AUTOSAR XML (schema 4-3-0)
package /ComponentTypes
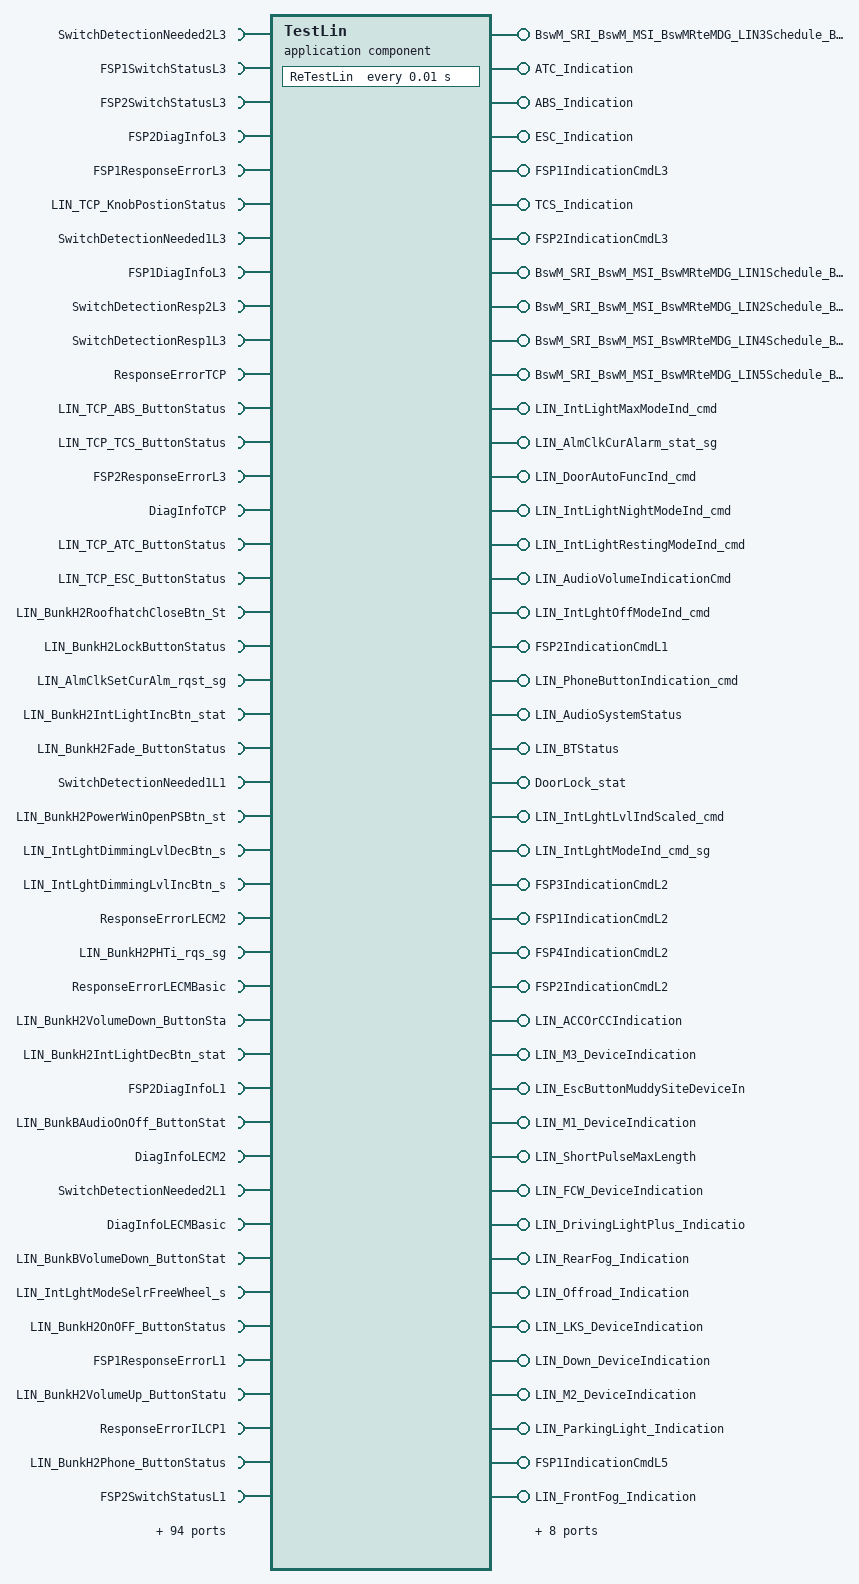
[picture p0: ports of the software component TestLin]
  application sw component type TestLin
    provide port BswM_SRI_BswM_MSI_BswMRteMDG_LIN3Schedule_BswM_MDGP_BswMRteMDG_LIN3Schedule: nonqueued-sender-com-spec=requestedMode, provided-interface=BswM_SRI_BswM_MSI_BswMRteMDG_LIN3Schedule_BswM_MDGP_BswMRteMDG_LIN3Schedule
    17 x require port:
      SwitchDetectionNeeded2L3: nonqueued-receiver-com-spec{data-element=SwitchDetectionNeeded2L3, init-value=0}, required-interface=SwitchDetectionNeeded2L3
      FSP1SwitchStatusL3: nonqueued-receiver-com-spec{data-element=FSP1SwitchStatusL3, init-value=0}, required-interface=FSP1SwitchStatusL3
      FSP2SwitchStatusL3: nonqueued-receiver-com-spec{data-element=FSP2SwitchStatusL3, init-value=0}, required-interface=FSP2SwitchStatusL3
      FSP2DiagInfoL3: nonqueued-receiver-com-spec{data-element=FSP2DiagInfoL3, init-value=0}, required-interface=FSP2DiagInfoL3
      FSP1ResponseErrorL3: nonqueued-receiver-com-spec{data-element=FSP1ResponseErrorL3, init-value=0}, required-interface=FSP1ResponseErrorL3
      LIN_TCP_KnobPostionStatus: nonqueued-receiver-com-spec{data-element=LIN_TCP_KnobPostionStatus, init-value=7}, required-interface=LIN_TCP_KnobPostionStatus
      SwitchDetectionNeeded1L3: nonqueued-receiver-com-spec{data-element=SwitchDetectionNeeded1L3, init-value=0}, required-interface=SwitchDetectionNeeded1L3
      FSP1DiagInfoL3: nonqueued-receiver-com-spec{data-element=FSP1DiagInfoL3, init-value=0}, required-interface=FSP1DiagInfoL3
      SwitchDetectionResp2L3: nonqueued-receiver-com-spec{data-element=SwitchDetectionResp2L3, init-value=8 x 0}, required-interface=SwitchDetectionResp2L3
      SwitchDetectionResp1L3: nonqueued-receiver-com-spec{data-element=SwitchDetectionResp1L3, init-value=8 x 0}, required-interface=SwitchDetectionResp1L3
      ResponseErrorTCP: nonqueued-receiver-com-spec{data-element=ResponseErrorTCP, init-value=0}, required-interface=ResponseErrorTCP
      LIN_TCP_ABS_ButtonStatus: nonqueued-receiver-com-spec{data-element=LIN_TCP_ABS_ButtonStatus, init-value=3}, required-interface=LIN_TCP_ABS_ButtonStatus
      LIN_TCP_TCS_ButtonStatus: nonqueued-receiver-com-spec{data-element=LIN_TCP_TCS_ButtonStatus, init-value=3}, required-interface=LIN_TCP_TCS_ButtonStatus
      FSP2ResponseErrorL3: nonqueued-receiver-com-spec{data-element=FSP2ResponseErrorL3, init-value=0}, required-interface=FSP2ResponseErrorL3
      DiagInfoTCP: nonqueued-receiver-com-spec{data-element=DiagInfoTCP, init-value=0}, required-interface=DiagInfoTCP
      LIN_TCP_ATC_ButtonStatus: nonqueued-receiver-com-spec{data-element=LIN_TCP_ATC_ButtonStatus, init-value=3}, required-interface=LIN_TCP_ATC_ButtonStatus
      LIN_TCP_ESC_ButtonStatus: nonqueued-receiver-com-spec{data-element=LIN_TCP_ESC_ButtonStatus, init-value=3}, required-interface=LIN_TCP_ESC_ButtonStatus
    10 x provide port:
      ATC_Indication: nonqueued-sender-com-spec{data-element=ATC_Indication, init-value=3}, provided-interface=ATC_Indication
      ABS_Indication: nonqueued-sender-com-spec{data-element=ABS_Indication, init-value=3}, provided-interface=ABS_Indication
      ESC_Indication: nonqueued-sender-com-spec{data-element=ESC_Indication, init-value=3}, provided-interface=ESC_Indication
      FSP1IndicationCmdL3: nonqueued-sender-com-spec{data-element=FSP1IndicationCmdL3, init-value=0}, provided-interface=FSP1IndicationCmdL3
      TCS_Indication: nonqueued-sender-com-spec{data-element=TCS_Indication, init-value=3}, provided-interface=TCS_Indication
      FSP2IndicationCmdL3: nonqueued-sender-com-spec{data-element=FSP2IndicationCmdL3, init-value=0}, provided-interface=FSP2IndicationCmdL3
      BswM_SRI_BswM_MSI_BswMRteMDG_LIN1Schedule_BswM_MDGP_BswMRteMDG_LIN1Schedule: nonqueued-sender-com-spec=requestedMode, provided-interface=BswM_SRI_BswM_MSI_BswMRteMDG_LIN1Schedule_BswM_MDGP_BswMRteMDG_LIN1Schedule
      BswM_SRI_BswM_MSI_BswMRteMDG_LIN2Schedule_BswM_MDGP_BswMRteMDG_LIN2Schedule: nonqueued-sender-com-spec=requestedMode, provided-interface=BswM_SRI_BswM_MSI_BswMRteMDG_LIN2Schedule_BswM_MDGP_BswMRteMDG_LIN2Schedule
      BswM_SRI_BswM_MSI_BswMRteMDG_LIN4Schedule_BswM_MDGP_BswMRteMDG_LIN4Schedule: nonqueued-sender-com-spec=requestedMode, provided-interface=BswM_SRI_BswM_MSI_BswMRteMDG_LIN4Schedule_BswM_MDGP_BswMRteMDG_LIN4Schedule
      BswM_SRI_BswM_MSI_BswMRteMDG_LIN5Schedule_BswM_MDGP_BswMRteMDG_LIN5Schedule: nonqueued-sender-com-spec=requestedMode, provided-interface=BswM_SRI_BswM_MSI_BswMRteMDG_LIN5Schedule_BswM_MDGP_BswMRteMDG_LIN5Schedule
    47 x require port:
      LIN_BunkH2RoofhatchCloseBtn_St: nonqueued-receiver-com-spec{data-element=LIN_BunkH2RoofhatchCloseBtn_St, init-value=3}, required-interface=LIN_BunkH2RoofhatchCloseBtn_St
      LIN_BunkH2LockButtonStatus: nonqueued-receiver-com-spec{data-element=LIN_BunkH2LockButtonStatus, init-value=3}, required-interface=LIN_BunkH2LockButtonStatus
      LIN_AlmClkSetCurAlm_rqst_sg: nonqueued-receiver-com-spec{data-element=LIN_AlmClkSetCurAlm_rqst_sg, init-value=fields=[LIN_AlmClkSetCurAlm_rqst_SetMin:63, LIN_AlmClkSetCurAlm_rqst_Type:7, LIN_AlmClkSetCurAlm_rqst_ID:127, LIN_AlmClkSetCurAlm_rqst_SetHr:31, LIN_AlmClkSetCurAlm_rqst_Stat:0]}, required-interface=LIN_AlmClkSetCurAlm_rqst_sg
      LIN_BunkH2IntLightIncBtn_stat: nonqueued-receiver-com-spec{data-element=LIN_BunkH2IntLightIncBtn_stat, init-value=3}, required-interface=LIN_BunkH2IntLightIncBtn_stat
      LIN_BunkH2Fade_ButtonStatus: nonqueued-receiver-com-spec{data-element=LIN_BunkH2Fade_ButtonStatus, init-value=3}, required-interface=LIN_BunkH2Fade_ButtonStatus
      SwitchDetectionNeeded1L1: nonqueued-receiver-com-spec{data-element=SwitchDetectionNeeded1L1, alive-timeout=120, init-value=0}, required-interface=SwitchDetectionNeeded1L1
      LIN_BunkH2PowerWinOpenPSBtn_st: nonqueued-receiver-com-spec{data-element=LIN_BunkH2PowerWinOpenPSBtn_st, init-value=3}, required-interface=LIN_BunkH2PowerWinOpenPSBtn_st
      LIN_IntLghtDimmingLvlDecBtn_s: nonqueued-receiver-com-spec{data-element=LIN_IntLghtDimmingLvlDecBtn_s, alive-timeout=120, init-value=3}, required-interface=LIN_IntLghtDimmingLvlDecBtn_s
      LIN_IntLghtDimmingLvlIncBtn_s: nonqueued-receiver-com-spec{data-element=LIN_IntLghtDimmingLvlIncBtn_s, alive-timeout=120, init-value=3}, required-interface=LIN_IntLghtDimmingLvlIncBtn_s
      ResponseErrorLECM2: nonqueued-receiver-com-spec{data-element=ResponseErrorLECM2, init-value=0}, required-interface=ResponseErrorLECM2
      LIN_BunkH2PHTi_rqs_sg: nonqueued-receiver-com-spec{data-element=LIN_BunkH2PHTi_rqs_sg, init-value=fields=[LIN_BunkH2PHTi_rqs_StartTimeHr:255, LIN_BunkH2PHTi_rqs_Timer_cmd:7, LIN_BunkH2PHTi_rqs_DurnTimeHr:255, LIN_BunkH2PHTi_rqs_StartTimeMin:255, LIN_BunkH2PHTi_rqs_DurnTimeMin:255]}, required-interface=LIN_BunkH2PHTi_rqs_sg
      ResponseErrorLECMBasic: nonqueued-receiver-com-spec{data-element=ResponseErrorLECMBasic, init-value=0}, required-interface=ResponseErrorLECMBasic
      LIN_BunkH2VolumeDown_ButtonSta: nonqueued-receiver-com-spec{data-element=LIN_BunkH2VolumeDown_ButtonSta, init-value=3}, required-interface=LIN_BunkH2VolumeDown_ButtonSta
      LIN_BunkH2IntLightDecBtn_stat: nonqueued-receiver-com-spec{data-element=LIN_BunkH2IntLightDecBtn_stat, init-value=3}, required-interface=LIN_BunkH2IntLightDecBtn_stat
      FSP2DiagInfoL1: nonqueued-receiver-com-spec{data-element=FSP2DiagInfoL1, alive-timeout=120, init-value=0}, required-interface=FSP2DiagInfoL1
      LIN_BunkBAudioOnOff_ButtonStat: nonqueued-receiver-com-spec{data-element=LIN_BunkBAudioOnOff_ButtonStat, init-value=3}, required-interface=LIN_BunkBAudioOnOff_ButtonStat
      DiagInfoLECM2: nonqueued-receiver-com-spec{data-element=DiagInfoLECM2, init-value=0}, required-interface=DiagInfoLECM2
      SwitchDetectionNeeded2L1: nonqueued-receiver-com-spec{data-element=SwitchDetectionNeeded2L1, alive-timeout=120, init-value=0}, required-interface=SwitchDetectionNeeded2L1
      DiagInfoLECMBasic: nonqueued-receiver-com-spec{data-element=DiagInfoLECMBasic, init-value=0}, required-interface=DiagInfoLECMBasic
      LIN_BunkBVolumeDown_ButtonStat: nonqueued-receiver-com-spec{data-element=LIN_BunkBVolumeDown_ButtonStat, init-value=3}, required-interface=LIN_BunkBVolumeDown_ButtonStat
      LIN_IntLghtModeSelrFreeWheel_s: nonqueued-receiver-com-spec{data-element=LIN_IntLghtModeSelrFreeWheel_s, alive-timeout=140, init-value=15}, required-interface=LIN_IntLghtModeSelrFreeWheel_s
      LIN_BunkH2OnOFF_ButtonStatus: nonqueued-receiver-com-spec{data-element=LIN_BunkH2OnOFF_ButtonStatus, init-value=3}, required-interface=LIN_BunkH2OnOFF_ButtonStatus
      FSP1ResponseErrorL1: nonqueued-receiver-com-spec{data-element=FSP1ResponseErrorL1, alive-timeout=140, init-value=0}, required-interface=FSP1ResponseErrorL1
      LIN_BunkH2VolumeUp_ButtonStatu: nonqueued-receiver-com-spec{data-element=LIN_BunkH2VolumeUp_ButtonStatu, init-value=3}, required-interface=LIN_BunkH2VolumeUp_ButtonStatu
      ResponseErrorILCP1: nonqueued-receiver-com-spec{data-element=ResponseErrorILCP1, alive-timeout=120, init-value=0}, required-interface=ResponseErrorILCP1
      LIN_BunkH2Phone_ButtonStatus: nonqueued-receiver-com-spec{data-element=LIN_BunkH2Phone_ButtonStatus, init-value=3}, required-interface=LIN_BunkH2Phone_ButtonStatus
      FSP2SwitchStatusL1: nonqueued-receiver-com-spec{data-element=FSP2SwitchStatusL1, alive-timeout=140, init-value=0}, required-interface=FSP2SwitchStatusL1
      FSP2ResponseErrorL1: nonqueued-receiver-com-spec{data-element=FSP2ResponseErrorL1, alive-timeout=140, init-value=0}, required-interface=FSP2ResponseErrorL1
      LIN_BunkH2PowerWinCloseDSBtn_s: nonqueued-receiver-com-spec{data-element=LIN_BunkH2PowerWinCloseDSBtn_s, init-value=3}, required-interface=LIN_BunkH2PowerWinCloseDSBtn_s
      LIN_BunkH2PowerWinOpenDSBtn_st: nonqueued-receiver-com-spec{data-element=LIN_BunkH2PowerWinOpenDSBtn_st, init-value=3}, required-interface=LIN_BunkH2PowerWinOpenDSBtn_st
      LIN_DoorAutoFuncBtn_stat: nonqueued-receiver-com-spec{data-element=LIN_DoorAutoFuncBtn_stat, alive-timeout=120, init-value=3}, required-interface=LIN_DoorAutoFuncBtn_stat
      LIN_BunkH2TempDec_ButtonStatus: nonqueued-receiver-com-spec{data-element=LIN_BunkH2TempDec_ButtonStatus, init-value=3}, required-interface=LIN_BunkH2TempDec_ButtonStatus
      LIN_BunkBVolumeUp_ButtonStat: nonqueued-receiver-com-spec{data-element=LIN_BunkBVolumeUp_ButtonStat, init-value=3}, required-interface=LIN_BunkBVolumeUp_ButtonStat
      LIN_BunkBIntLightActvnBtn_stat: nonqueued-receiver-com-spec{data-element=LIN_BunkBIntLightActvnBtn_stat, init-value=3}, required-interface=LIN_BunkBIntLightActvnBtn_stat
      LIN_BunkH2PowerWinClosePSBtn_s: nonqueued-receiver-com-spec{data-element=LIN_BunkH2PowerWinClosePSBtn_s, init-value=3}, required-interface=LIN_BunkH2PowerWinClosePSBtn_s
      LIN_BunkBParkHeater_ButtonStat: nonqueued-receiver-com-spec{data-element=LIN_BunkBParkHeater_ButtonStat, init-value=3}, required-interface=LIN_BunkBParkHeater_ButtonStat
      LIN_BunkH2ParkHeater_ButtonSta: nonqueued-receiver-com-spec{data-element=LIN_BunkH2ParkHeater_ButtonSta, init-value=3}, required-interface=LIN_BunkH2ParkHeater_ButtonSta
      LIN_BunkBTempInc_ButtonStat: nonqueued-receiver-com-spec{data-element=LIN_BunkBTempInc_ButtonStat, init-value=3}, required-interface=LIN_BunkBTempInc_ButtonStat
      LIN_BunkH2AudioOnOff_ButtonSta: nonqueued-receiver-com-spec{data-element=LIN_BunkH2AudioOnOff_ButtonSta, init-value=3}, required-interface=LIN_BunkH2AudioOnOff_ButtonSta
      SwitchDetectionResp2L1: nonqueued-receiver-com-spec{data-element=SwitchDetectionResp2L1, init-value=8 x 0}, required-interface=SwitchDetectionResp2L1
      LIN_BunkH2IntLightActvnBtn_sta: nonqueued-receiver-com-spec{data-element=LIN_BunkH2IntLightActvnBtn_sta, init-value=3}, required-interface=LIN_BunkH2IntLightActvnBtn_sta
      LIN_BunkH2RoofhatchOpenBtn_Sta: nonqueued-receiver-com-spec{data-element=LIN_BunkH2RoofhatchOpenBtn_Sta, init-value=3}, required-interface=LIN_BunkH2RoofhatchOpenBtn_Sta
      SwitchDetectionResp1L1: nonqueued-receiver-com-spec{data-element=SwitchDetectionResp1L1, init-value=8 x 0}, required-interface=SwitchDetectionResp1L1
      FSP1DiagInfoL1: nonqueued-receiver-com-spec{data-element=FSP1DiagInfoL1, alive-timeout=120, init-value=0}, required-interface=FSP1DiagInfoL1
      DiagInfoILCP1: nonqueued-receiver-com-spec{data-element=DiagInfoILCP1, alive-timeout=120, init-value=0}, required-interface=DiagInfoILCP1
      LIN_BunkBTempDec_ButtonStat: nonqueued-receiver-com-spec{data-element=LIN_BunkBTempDec_ButtonStat, init-value=3}, required-interface=LIN_BunkBTempDec_ButtonStat
      LIN_BunkH2TempInc_ButtonStatus: nonqueued-receiver-com-spec{data-element=LIN_BunkH2TempInc_ButtonStatus, init-value=3}, required-interface=LIN_BunkH2TempInc_ButtonStatus
    14 x provide port:
      LIN_IntLightMaxModeInd_cmd: nonqueued-sender-com-spec{data-element=LIN_IntLightMaxModeInd_cmd, init-value=0}, provided-interface=LIN_IntLightMaxModeInd_cmd
      LIN_AlmClkCurAlarm_stat_sg: nonqueued-sender-com-spec{data-element=LIN_AlmClkCurAlarm_stat_sg, init-value=fields=[LIN_AlmClkCurAlarm_stat_Stat:0, LIN_AlmClkCurAlarm_stat_SetHr:31, LIN_AlmClkCurAlarm_stat_Type:7, LIN_AlmClkCurAlarm_stat_SetMin:63, LIN_AlmClkCurAlarm_stat_ID:127]}, provided-interface=LIN_AlmClkCurAlarm_stat_sg
      LIN_DoorAutoFuncInd_cmd: nonqueued-sender-com-spec{data-element=LIN_DoorAutoFuncInd_cmd, init-value=0}, provided-interface=LIN_DoorAutoFuncInd_cmd
      LIN_IntLightNightModeInd_cmd: nonqueued-sender-com-spec{data-element=LIN_IntLightNightModeInd_cmd, init-value=0}, provided-interface=LIN_IntLightNightModeInd_cmd
      LIN_IntLightRestingModeInd_cmd: nonqueued-sender-com-spec{data-element=LIN_IntLightRestingModeInd_cmd, init-value=0}, provided-interface=LIN_IntLightRestingModeInd_cmd
      LIN_AudioVolumeIndicationCmd: nonqueued-sender-com-spec{data-element=LIN_AudioVolumeIndicationCmd, init-value=0}, provided-interface=LIN_AudioVolumeIndicationCmd
      LIN_IntLghtOffModeInd_cmd: nonqueued-sender-com-spec{data-element=LIN_IntLghtOffModeInd_cmd, init-value=0}, provided-interface=LIN_IntLghtOffModeInd_cmd
      FSP2IndicationCmdL1: nonqueued-sender-com-spec{data-element=FSP2IndicationCmdL1, init-value=0}, provided-interface=FSP2IndicationCmdL1
      LIN_PhoneButtonIndication_cmd: nonqueued-sender-com-spec{data-element=LIN_PhoneButtonIndication_cmd, init-value=0}, provided-interface=LIN_PhoneButtonIndication_cmd
      LIN_AudioSystemStatus: nonqueued-sender-com-spec{data-element=LIN_AudioSystemStatus, init-value=3}, provided-interface=LIN_AudioSystemStatus
      LIN_BTStatus: nonqueued-sender-com-spec{data-element=LIN_BTStatus, init-value=3}, provided-interface=LIN_BTStatus
      DoorLock_stat: nonqueued-sender-com-spec{data-element=DoorLock_stat, init-value=15}, provided-interface=DoorLock_stat
      LIN_IntLghtLvlIndScaled_cmd: nonqueued-sender-com-spec{data-element=LIN_IntLghtLvlIndScaled_cmd, init-value=0}, provided-interface=LIN_IntLghtLvlIndScaled_cmd
      LIN_IntLghtModeInd_cmd_sg: nonqueued-sender-com-spec{data-element=LIN_IntLghtModeInd_cmd_sg, init-value=fields=[LIN_IntLghtModeInd_cmd_EventFlag:0, LIN_IntLghtModeInd_cmd_IL_Mode:7]}, provided-interface=LIN_IntLghtModeInd_cmd_sg
    20 x require port:
      FSP3ResponseErrorL2: nonqueued-receiver-com-spec{data-element=FSP3ResponseErrorL2, init-value=0}, required-interface=FSP3ResponseErrorL2
      FSP1SwitchStatusL2: nonqueued-receiver-com-spec{data-element=FSP1SwitchStatusL2, init-value=0}, required-interface=FSP1SwitchStatusL2
      SwitchDetectionResp1L2: nonqueued-receiver-com-spec{data-element=SwitchDetectionResp1L2, init-value=8 x 0}, required-interface=SwitchDetectionResp1L2
      SwitchDetectionNeeded2L2: nonqueued-receiver-com-spec{data-element=SwitchDetectionNeeded2L2, init-value=0}, required-interface=SwitchDetectionNeeded2L2
      FSP3SwitchStatusL2: nonqueued-receiver-com-spec{data-element=FSP3SwitchStatusL2, init-value=0}, required-interface=FSP3SwitchStatusL2
      FSP3DiagInfoL2: nonqueued-receiver-com-spec{data-element=FSP3DiagInfoL2, init-value=0}, required-interface=FSP3DiagInfoL2
      FSP1DiagInfoL2: nonqueued-receiver-com-spec{data-element=FSP1DiagInfoL2, init-value=0}, required-interface=FSP1DiagInfoL2
      FSP4ResponseErrorL2: nonqueued-receiver-com-spec{data-element=FSP4ResponseErrorL2, init-value=0}, required-interface=FSP4ResponseErrorL2
      FSP4DiagInfoL2: nonqueued-receiver-com-spec{data-element=FSP4DiagInfoL2, init-value=0}, required-interface=FSP4DiagInfoL2
      FSP2DiagInfoL2: nonqueued-receiver-com-spec{data-element=FSP2DiagInfoL2, init-value=0}, required-interface=FSP2DiagInfoL2
      SwitchDetectionResp4L2: nonqueued-receiver-com-spec{data-element=SwitchDetectionResp4L2, init-value=8 x 0}, required-interface=SwitchDetectionResp4L2
      FSP4SwitchStatusL2: nonqueued-receiver-com-spec{data-element=FSP4SwitchStatusL2, init-value=0}, required-interface=FSP4SwitchStatusL2
      FSP1ResponseErrorL2: nonqueued-receiver-com-spec{data-element=FSP1ResponseErrorL2, init-value=0}, required-interface=FSP1ResponseErrorL2
      SwitchDetectionResp2L2: nonqueued-receiver-com-spec{data-element=SwitchDetectionResp2L2, init-value=8 x 0}, required-interface=SwitchDetectionResp2L2
      FSP2SwitchStatusL2: nonqueued-receiver-com-spec{data-element=FSP2SwitchStatusL2, init-value=0}, required-interface=FSP2SwitchStatusL2
      SwitchDetectionNeeded1L2: nonqueued-receiver-com-spec{data-element=SwitchDetectionNeeded1L2, init-value=0}, required-interface=SwitchDetectionNeeded1L2
      FSP2ResponseErrorL2: nonqueued-receiver-com-spec{data-element=FSP2ResponseErrorL2, init-value=0}, required-interface=FSP2ResponseErrorL2
      SwitchDetectionNeeded3L2: nonqueued-receiver-com-spec{data-element=SwitchDetectionNeeded3L2, init-value=0}, required-interface=SwitchDetectionNeeded3L2
      SwitchDetectionResp3L2: nonqueued-receiver-com-spec{data-element=SwitchDetectionResp3L2, init-value=8 x 0}, required-interface=SwitchDetectionResp3L2
      SwitchDetectionNeeded4L2: nonqueued-receiver-com-spec{data-element=SwitchDetectionNeeded4L2, init-value=0}, required-interface=SwitchDetectionNeeded4L2
    4 x provide port:
      FSP3IndicationCmdL2: nonqueued-sender-com-spec{data-element=FSP3IndicationCmdL2, init-value=0}, provided-interface=FSP3IndicationCmdL2
      FSP1IndicationCmdL2: nonqueued-sender-com-spec{data-element=FSP1IndicationCmdL2, init-value=0}, provided-interface=FSP1IndicationCmdL2
      FSP4IndicationCmdL2: nonqueued-sender-com-spec{data-element=FSP4IndicationCmdL2, init-value=0}, provided-interface=FSP4IndicationCmdL2
      FSP2IndicationCmdL2: nonqueued-sender-com-spec{data-element=FSP2IndicationCmdL2, init-value=0}, provided-interface=FSP2IndicationCmdL2
    54 x require port:
      ResponseErrorELCP1: nonqueued-receiver-com-spec{data-element=ResponseErrorELCP1, init-value=0}, required-interface=ResponseErrorELCP1
      SwitchDetectionNeeded1L5: nonqueued-receiver-com-spec{data-element=SwitchDetectionNeeded1L5, init-value=0}, required-interface=SwitchDetectionNeeded1L5
      LIN_WRDownButtonStatus: nonqueued-receiver-com-spec{data-element=LIN_WRDownButtonStatus, init-value=7}, required-interface=LIN_WRDownButtonStatus
      FSP1SwitchStatusL4: nonqueued-receiver-com-spec{data-element=FSP1SwitchStatusL4, init-value=0}, required-interface=FSP1SwitchStatusL4
      LIN_IntLghtNightModeBt2_s: nonqueued-receiver-com-spec{data-element=LIN_IntLghtNightModeBt2_s, init-value=3}, required-interface=LIN_IntLghtNightModeBt2_s
      ResponseErrorILCP2: nonqueued-receiver-com-spec{data-element=ResponseErrorILCP2, init-value=0}, required-interface=ResponseErrorILCP2
      FSP1ResponseErrorL4: nonqueued-receiver-com-spec{data-element=FSP1ResponseErrorL4, init-value=0}, required-interface=FSP1ResponseErrorL4
      LIN_DifflockMode_Wheelstatus: nonqueued-receiver-com-spec{data-element=LIN_DifflockMode_Wheelstatus, init-value=15}, required-interface=LIN_DifflockMode_Wheelstatus
      LIN_LKSPushButton: nonqueued-receiver-com-spec{data-element=LIN_LKSPushButton, init-value=3}, required-interface=LIN_LKSPushButton
      LIN_LightMode_Status_2: nonqueued-receiver-com-spec{data-element=LIN_LightMode_Status_2, init-value=15}, required-interface=LIN_LightMode_Status_2
      LIN_SpeedControlModeWheelStat: nonqueued-receiver-com-spec{data-element=LIN_SpeedControlModeWheelStat, init-value=15}, required-interface=LIN_SpeedControlModeWheelStat
      LIN_BackButtonStatus: nonqueued-receiver-com-spec{data-element=LIN_BackButtonStatus, init-value=3}, required-interface=LIN_BackButtonStatus
      LIN_MemButtonStatus: nonqueued-receiver-com-spec{data-element=LIN_MemButtonStatus, init-value=3}, required-interface=LIN_MemButtonStatus
      SwitchDetectionResp1L4: nonqueued-receiver-com-spec{data-element=SwitchDetectionResp1L4, init-value=8 x 0}, required-interface=SwitchDetectionResp1L4
      LIN_SelectButtonStatus: nonqueued-receiver-com-spec{data-element=LIN_SelectButtonStatus, init-value=3}, required-interface=LIN_SelectButtonStatus
      LIN_IntLghtDimmingLvlFreeWhl_s: nonqueued-receiver-com-spec{data-element=LIN_IntLghtDimmingLvlFreeWhl_s, init-value=15}, required-interface=LIN_IntLghtDimmingLvlFreeWhl_s
      LIN_FogLightRear_ButtonStat_1: nonqueued-receiver-com-spec{data-element=LIN_FogLightRear_ButtonStat_1, init-value=3}, required-interface=LIN_FogLightRear_ButtonStat_1
      LIN_SpeedControlModeButtonStat: nonqueued-receiver-com-spec{data-element=LIN_SpeedControlModeButtonStat, init-value=3}, required-interface=LIN_SpeedControlModeButtonStat
      DiagInfoDLFW: nonqueued-receiver-com-spec{data-element=DiagInfoDLFW, init-value=0}, required-interface=DiagInfoDLFW
      LIN_FogLightRear_ButtonStat_2: nonqueued-receiver-com-spec{data-element=LIN_FogLightRear_ButtonStat_2, init-value=3}, required-interface=LIN_FogLightRear_ButtonStat_2
      LIN_StopButtonStatus: nonqueued-receiver-com-spec{data-element=LIN_StopButtonStatus, init-value=3}, required-interface=LIN_StopButtonStatus
      DiagInfoRCECS: nonqueued-receiver-com-spec{data-element=DiagInfoRCECS, init-value=0}, required-interface=DiagInfoRCECS
      LIN_LightMode_Status_1: nonqueued-receiver-com-spec{data-element=LIN_LightMode_Status_1, init-value=15}, required-interface=LIN_LightMode_Status_1
      LIN_WRUpButtonStatus: nonqueued-receiver-com-spec{data-element=LIN_WRUpButtonStatus, init-value=7}, required-interface=LIN_WRUpButtonStatus
      LIN_DifflockDeactivationBtn_st: nonqueued-receiver-com-spec{data-element=LIN_DifflockDeactivationBtn_st, init-value=3}, required-interface=LIN_DifflockDeactivationBtn_st
      LIN_IntLghtCenterBtnFreeWhl_s: nonqueued-receiver-com-spec{data-element=LIN_IntLghtCenterBtnFreeWhl_s, init-value=3}, required-interface=LIN_IntLghtCenterBtnFreeWhl_s
      SwitchDetectionResp1L5: nonqueued-receiver-com-spec{data-element=SwitchDetectionResp1L5, init-value=8 x 0}, required-interface=SwitchDetectionResp1L5
      FSP1DiagInfoL5: nonqueued-receiver-com-spec{data-element=FSP1DiagInfoL5, init-value=0}, required-interface=FSP1DiagInfoL5
      LIN_EscButtonMuddySiteStatus: nonqueued-receiver-com-spec{data-element=LIN_EscButtonMuddySiteStatus, init-value=3}, required-interface=LIN_EscButtonMuddySiteStatus
      FSP1SwitchStatusL5: nonqueued-receiver-com-spec{data-element=FSP1SwitchStatusL5, init-value=0}, required-interface=FSP1SwitchStatusL5
      SwitchDetectionNeeded1L4: nonqueued-receiver-com-spec{data-element=SwitchDetectionNeeded1L4, init-value=0}, required-interface=SwitchDetectionNeeded1L4
      LIN_AdjustButtonStatus: nonqueued-receiver-com-spec{data-element=LIN_AdjustButtonStatus, init-value=3}, required-interface=LIN_AdjustButtonStatus
      ResponseErrorDLFW: nonqueued-receiver-com-spec{data-element=ResponseErrorDLFW, init-value=0}, required-interface=ResponseErrorDLFW
      LIN_BlackPanelMode_ButtonStat: nonqueued-receiver-com-spec{data-element=LIN_BlackPanelMode_ButtonStat, init-value=3}, required-interface=LIN_BlackPanelMode_ButtonStat
      FSP1DiagInfoL4: nonqueued-receiver-com-spec{data-element=FSP1DiagInfoL4, init-value=0}, required-interface=FSP1DiagInfoL4
      LIN_FCWPushButton: nonqueued-receiver-com-spec{data-element=LIN_FCWPushButton, init-value=3}, required-interface=LIN_FCWPushButton
      ResponseErrorRCECS: nonqueued-receiver-com-spec{data-element=ResponseErrorRCECS, init-value=0}, required-interface=ResponseErrorRCECS
      DiagInfoELCP2: nonqueued-receiver-com-spec{data-element=DiagInfoELCP2, init-value=0}, required-interface=DiagInfoELCP2
      DiagInfoCCFW: nonqueued-receiver-com-spec{data-element=DiagInfoCCFW, init-value=0}, required-interface=DiagInfoCCFW
      DiagInfoILCP2: nonqueued-receiver-com-spec{data-element=DiagInfoILCP2, init-value=0}, required-interface=DiagInfoILCP2
      DiagInfoELCP1: nonqueued-receiver-com-spec{data-element=DiagInfoELCP1, init-value=0}, required-interface=DiagInfoELCP1
      LIN_BackLightDimming_Status: nonqueued-receiver-com-spec{data-element=LIN_BackLightDimming_Status, init-value=31}, required-interface=LIN_BackLightDimming_Status
      FSP1ResponseErrorL5: nonqueued-receiver-com-spec{data-element=FSP1ResponseErrorL5, init-value=0}, required-interface=FSP1ResponseErrorL5
      LIN_DRL_ButtonStatus: nonqueued-receiver-com-spec{data-element=LIN_DRL_ButtonStatus, init-value=3}, required-interface=LIN_DRL_ButtonStatus
      ResponseErrorELCP2: nonqueued-receiver-com-spec{data-element=ResponseErrorELCP2, init-value=0}, required-interface=ResponseErrorELCP2
      ResponseErrorCCFW: nonqueued-receiver-com-spec{data-element=ResponseErrorCCFW, init-value=0}, required-interface=ResponseErrorCCFW
      LIN_LevelingThumbwheel_stat: nonqueued-receiver-com-spec{data-element=LIN_LevelingThumbwheel_stat, init-value=31}, required-interface=LIN_LevelingThumbwheel_stat
      LIN_Offroad_ButtonStatus: nonqueued-receiver-com-spec{data-element=LIN_Offroad_ButtonStatus, init-value=3}, required-interface=LIN_Offroad_ButtonStatus
      LIN_FogLightFront_ButtonStat_2: nonqueued-receiver-com-spec{data-element=LIN_FogLightFront_ButtonStat_2, init-value=3}, required-interface=LIN_FogLightFront_ButtonStat_2
      LIN_RearWorkProjector_BtnStat: nonqueued-receiver-com-spec{data-element=LIN_RearWorkProjector_BtnStat, init-value=3}, required-interface=LIN_RearWorkProjector_BtnStat
      LIN_HeadLampUpDown_SwitchStatu: nonqueued-receiver-com-spec{data-element=LIN_HeadLampUpDown_SwitchStatu, init-value=7}, required-interface=LIN_HeadLampUpDown_SwitchStatu
      LIN_FogLightFront_ButtonStat_1: nonqueued-receiver-com-spec{data-element=LIN_FogLightFront_ButtonStat_1, init-value=3}, required-interface=LIN_FogLightFront_ButtonStat_1
      LIN_IntLghtMaxModeBtnPnl2_s: nonqueued-receiver-com-spec{data-element=LIN_IntLghtMaxModeBtnPnl2_s, init-value=3}, required-interface=LIN_IntLghtMaxModeBtnPnl2_s
      LIN_IntLghtRestModeBtnPnl2_s: nonqueued-receiver-com-spec{data-element=LIN_IntLghtRestModeBtnPnl2_s, init-value=3}, required-interface=LIN_IntLghtRestModeBtnPnl2_s
    23 x provide port:
      LIN_ACCOrCCIndication: nonqueued-sender-com-spec{data-element=LIN_ACCOrCCIndication, init-value=0}, provided-interface=LIN_ACCOrCCIndication
      LIN_M3_DeviceIndication: nonqueued-sender-com-spec{data-element=LIN_M3_DeviceIndication, init-value=0}, provided-interface=LIN_M3_DeviceIndication
      LIN_EscButtonMuddySiteDeviceIn: nonqueued-sender-com-spec{data-element=LIN_EscButtonMuddySiteDeviceIn, init-value=0}, provided-interface=LIN_EscButtonMuddySiteDeviceIn
      LIN_M1_DeviceIndication: nonqueued-sender-com-spec{data-element=LIN_M1_DeviceIndication, init-value=0}, provided-interface=LIN_M1_DeviceIndication
      LIN_ShortPulseMaxLength: nonqueued-sender-com-spec{data-element=LIN_ShortPulseMaxLength, init-value=0}, provided-interface=LIN_ShortPulseMaxLength
      LIN_FCW_DeviceIndication: nonqueued-sender-com-spec{data-element=LIN_FCW_DeviceIndication, init-value=0}, provided-interface=LIN_FCW_DeviceIndication
      LIN_DrivingLightPlus_Indicatio: nonqueued-sender-com-spec{data-element=LIN_DrivingLightPlus_Indicatio, init-value=0}, provided-interface=LIN_DrivingLightPlus_Indicatio
      LIN_RearFog_Indication: nonqueued-sender-com-spec{data-element=LIN_RearFog_Indication, init-value=0}, provided-interface=LIN_RearFog_Indication
      LIN_Offroad_Indication: nonqueued-sender-com-spec{data-element=LIN_Offroad_Indication, init-value=0}, provided-interface=LIN_Offroad_Indication
      LIN_LKS_DeviceIndication: nonqueued-sender-com-spec{data-element=LIN_LKS_DeviceIndication, init-value=0}, provided-interface=LIN_LKS_DeviceIndication
      LIN_Down_DeviceIndication: nonqueued-sender-com-spec{data-element=LIN_Down_DeviceIndication, init-value=0}, provided-interface=LIN_Down_DeviceIndication
      LIN_M2_DeviceIndication: nonqueued-sender-com-spec{data-element=LIN_M2_DeviceIndication, init-value=0}, provided-interface=LIN_M2_DeviceIndication
      LIN_ParkingLight_Indication: nonqueued-sender-com-spec{data-element=LIN_ParkingLight_Indication, init-value=0}, provided-interface=LIN_ParkingLight_Indication
      FSP1IndicationCmdL5: nonqueued-sender-com-spec{data-element=FSP1IndicationCmdL5, init-value=0}, provided-interface=FSP1IndicationCmdL5
      LIN_FrontFog_Indication: nonqueued-sender-com-spec{data-element=LIN_FrontFog_Indication, init-value=0}, provided-interface=LIN_FrontFog_Indication
      LIN_ASLIndication: nonqueued-sender-com-spec{data-element=LIN_ASLIndication, init-value=0}, provided-interface=LIN_ASLIndication
      LIN_DaytimeRunningLight_Indica: nonqueued-sender-com-spec{data-element=LIN_DaytimeRunningLight_Indica, init-value=0}, provided-interface=LIN_DaytimeRunningLight_Indica
      LIN_DifflockOnOff_Indication: nonqueued-sender-com-spec{data-element=LIN_DifflockOnOff_Indication, init-value=0}, provided-interface=LIN_DifflockOnOff_Indication
      LIN_RearWorkProjector_Indicati: nonqueued-sender-com-spec{data-element=LIN_RearWorkProjector_Indicati, init-value=0}, provided-interface=LIN_RearWorkProjector_Indicati
      FSP1IndicationCmdL4: nonqueued-sender-com-spec{data-element=FSP1IndicationCmdL4, init-value=0}, provided-interface=FSP1IndicationCmdL4
      LIN_Adjust_DeviceIndication: nonqueued-sender-com-spec{data-element=LIN_Adjust_DeviceIndication, init-value=0}, provided-interface=LIN_Adjust_DeviceIndication
      LIN_DrivingLight_Indication: nonqueued-sender-com-spec{data-element=LIN_DrivingLight_Indication, init-value=0}, provided-interface=LIN_DrivingLight_Indication
      LIN_Up_DeviceIndication: nonqueued-sender-com-spec{data-element=LIN_Up_DeviceIndication, init-value=0}, provided-interface=LIN_Up_DeviceIndication
    behavior TestLin_InternalBehavior
      timing event TMT_ReTestLin: start-on-event=ReTestLin, period=0.01
      13 x data receive error event:
        DRET_Re_LIN0_FSP1_RxTimeout_FSP1DiagInfoL1_FSP1DiagInfoL1: start-on-event=Re_LIN0_FSP1_L1_FSP1DiagInfoL1_RxTimeout, data=FSP1DiagInfoL1.FSP1DiagInfoL1
        DRET_Re_LIN0_FSP2_L1_RxTimeout_FSP2DiagInfoL1_FSP2DiagInfoL1: start-on-event=Re_LIN0_FSP2_L1_FSP2DiagInfoL1_RxTimeout, data=FSP2DiagInfoL1.FSP2DiagInfoL1
        DRET_Re_LIN0_ILCP1_RxTimeout_DiagInfoILCP1_DiagInfoILCP1: start-on-event=Re_LIN0_ILCP1_DiagInfoILCP1_RxTimeout, data=DiagInfoILCP1.DiagInfoILCP1
        DRET_Re_LIN0_FSP1_L1_FSP1ResponseErrorL1_RxTimeout_FSP1ResponseErrorL1_FSP1ResponseErrorL1: start-on-event=Re_LIN0_FSP1_L1_FSP1ResponseErrorL1_RxTimeout, data=FSP1ResponseErrorL1.FSP1ResponseErrorL1
        DRET_Re_LIN0_FSP1_L1_SwitchDetectionNeeded1L1_RxTimeout_SwitchDetectionNeeded1L1_SwitchDetectionNeeded1L1: start-on-event=Re_LIN0_FSP1_L1_SwitchDetectionNeeded1L1_RxTimeout, data=SwitchDetectionNeeded1L1.SwitchDetectionNeeded1L1
        DRET_Re_LIN0_FSP2_L1_RxTimeout_1_FSP2ResponseErrorL1_FSP2ResponseErrorL1: start-on-event=Re_LIN0_FSP2_L1_FSP2ResponseErrorL1_RxTimeout, data=FSP2ResponseErrorL1.FSP2ResponseErrorL1
        DRET_Re_LIN0_FSP2_L1_RxTimeout_1_1_FSP2SwitchStatusL1_FSP2SwitchStatusL1: start-on-event=Re_LIN0_FSP2_L1_FSP2SwitchStatusL1_RxTimeout, data=FSP2SwitchStatusL1.FSP2SwitchStatusL1
        DRET_Re_LIN0_FSP2_L1_RxTimeout_1_1_1_SwitchDetectionNeeded2L1_SwitchDetectionNeeded2L1: start-on-event=Re_LIN0_FSP2_L1_SwitchDetectionNeeded2L1_RxTimeout, data=SwitchDetectionNeeded2L1.SwitchDetectionNeeded2L1
        DRET_Re_LIN0_ILCP1_RxTimeout_1_LIN_DoorAutoFuncBtn_stat_LIN_DoorAutoFuncBtn_stat: start-on-event=Re_LIN0_ILCP1_LIN_DoorAutoFuncBtn_stat_RxTimeout, data=LIN_DoorAutoFuncBtn_stat.LIN_DoorAutoFuncBtn_stat
        DRET_Re_LIN0_ILCP1_RxTimeout_1_1_LIN_IntLghtDimmingLvlDecBtn_s_LIN_IntLghtDimmingLvlDecBtn_s: start-on-event=Re_LIN0_ILCP1_LIN_IntLghtDimmingLvlDecBtn_s_RxTimeout, data=LIN_IntLghtDimmingLvlDecBtn_s.LIN_IntLghtDimmingLvlDecBtn_s
        DRET_Re_LIN0_ILCP1_RxTimeout_1_1_1_LIN_IntLghtDimmingLvlIncBtn_s_LIN_IntLghtDimmingLvlIncBtn_s: start-on-event=Re_LIN0_ILCP1_LIN_IntLghtDimmingLvlIncBtn_s_RxTimeout, data=LIN_IntLghtDimmingLvlIncBtn_s.LIN_IntLghtDimmingLvlIncBtn_s
        DRET_Re_LIN0_ILCP1_RxTimeout_1_1_1_1_LIN_IntLghtModeSelrFreeWheel_s_LIN_IntLghtModeSelrFreeWheel_s: start-on-event=Re_LIN0_ILCP1_LIN_IntLghtModeSelrFreeWheel_s_RxTimeout, data=LIN_IntLghtModeSelrFreeWheel_s.LIN_IntLghtModeSelrFreeWheel_s
        DRET_Re_LIN0_ILCP1_RxTimeout_1_1_1_1_1_ResponseErrorILCP1_ResponseErrorILCP1: start-on-event=Re_LIN0_ILCP1_ResponseErrorILCP1_RxTimeout, data=ResponseErrorILCP1.ResponseErrorILCP1
      13 x data received event:
        DRT_Re_LIN0_FSP1_L1_FSP1DiagInfoL1_RXCbk_FSP1DiagInfoL1_FSP1DiagInfoL1: start-on-event=Re_LIN0_FSP1_L1_FSP1DiagInfoL1_RXCbk, data=FSP1DiagInfoL1.FSP1DiagInfoL1
        DRT_Re_LIN0_FSP1_L1_FSP1ResponseErrorL1_RXCbk_FSP1ResponseErrorL1_FSP1ResponseErrorL1: start-on-event=Re_LIN0_FSP1_L1_FSP1ResponseErrorL1_RXCbk, data=FSP1ResponseErrorL1.FSP1ResponseErrorL1
        DRT_Re_LIN0_FSP1_L1_SwitchDetectionNeeded1L1_RXCbk_SwitchDetectionNeeded1L1_SwitchDetectionNeeded1L1: start-on-event=Re_LIN0_FSP1_L1_SwitchDetectionNeeded1L1_RXCbk, data=SwitchDetectionNeeded1L1.SwitchDetectionNeeded1L1
        DRT_Re_LIN0_FSP2_L1_FSP2DiagInfoL1_RXCbk_FSP2DiagInfoL1_FSP2DiagInfoL1: start-on-event=Re_LIN0_FSP2_L1_FSP2DiagInfoL1_RXCbk, data=FSP2DiagInfoL1.FSP2DiagInfoL1
        DRT_Re_LIN0_FSP2_L1_FSP2ResponseErrorL1_RXCbk_FSP2ResponseErrorL1_FSP2ResponseErrorL1: start-on-event=Re_LIN0_FSP2_L1_FSP2ResponseErrorL1_RXCbk, data=FSP2ResponseErrorL1.FSP2ResponseErrorL1
        DRT_Re_LIN0_FSP2_L1_FSP2SwitchStatusL1_RXCbk_FSP2SwitchStatusL1_FSP2SwitchStatusL1: start-on-event=Re_LIN0_FSP2_L1_FSP2SwitchStatusL1_RXCbk, data=FSP2SwitchStatusL1.FSP2SwitchStatusL1
        DRT_Re_LIN0_FSP2_L1_SwitchDetectionNeeded2L1_RXCbk_SwitchDetectionNeeded2L1_SwitchDetectionNeeded2L1: start-on-event=Re_LIN0_FSP2_L1_SwitchDetectionNeeded2L1_RXCbk, data=SwitchDetectionNeeded2L1.SwitchDetectionNeeded2L1
        DRT_Re_LIN0_ILCP1_DiagInfoILCP1_RXCbk_DiagInfoILCP1_DiagInfoILCP1: start-on-event=Re_LIN0_ILCP1_DiagInfoILCP1_RXCbk, data=DiagInfoILCP1.DiagInfoILCP1
        DRT_Re_LIN0_ILCP1_LIN_DoorAutoFuncBtn_stat_RXCbk_LIN_DoorAutoFuncBtn_stat_LIN_DoorAutoFuncBtn_stat: start-on-event=Re_LIN0_ILCP1_LIN_DoorAutoFuncBtn_stat_RXCbk, data=LIN_DoorAutoFuncBtn_stat.LIN_DoorAutoFuncBtn_stat
        DRT_Re_LIN0_ILCP1_LIN_IntLghtDimmingLvlDecBtn_s_RXCbk_LIN_IntLghtDimmingLvlDecBtn_s_LIN_IntLghtDimmingLvlDecBtn_s: start-on-event=Re_LIN0_ILCP1_LIN_IntLghtDimmingLvlDecBtn_s_RXCbk, data=LIN_IntLghtDimmingLvlDecBtn_s.LIN_IntLghtDimmingLvlDecBtn_s
        DRT_Re_LIN0_ILCP1_LIN_IntLghtDimmingLvlIncBtn_s_RXCbk_LIN_IntLghtDimmingLvlIncBtn_s_LIN_IntLghtDimmingLvlIncBtn_s: start-on-event=Re_LIN0_ILCP1_LIN_IntLghtDimmingLvlIncBtn_s_RXCbk, data=LIN_IntLghtDimmingLvlIncBtn_s.LIN_IntLghtDimmingLvlIncBtn_s
        DRT_Re_LIN0_ILCP1_LIN_IntLghtModeSelrFreeWheel_s_RXCbk_LIN_IntLghtModeSelrFreeWheel_s_LIN_IntLghtModeSelrFreeWheel_s: start-on-event=Re_LIN0_ILCP1_LIN_IntLghtModeSelrFreeWheel_s_RXCbk, data=LIN_IntLghtModeSelrFreeWheel_s.LIN_IntLghtModeSelrFreeWheel_s
        DRT_Re_LIN0_ILCP1_ResponseErrorILCP1_RXCbk_ResponseErrorILCP1_ResponseErrorILCP1: start-on-event=Re_LIN0_ILCP1_ResponseErrorILCP1_RXCbk, data=ResponseErrorILCP1.ResponseErrorILCP1
      27 x runnable:
        ReTestLin
          data-receive-point-by-arguments:
            138 x access:
              REC_DiagInfoTCP_DiagInfoTCP: accessed-variable=DiagInfoTCP.DiagInfoTCP
              REC_FSP1DiagInfoL3_FSP1DiagInfoL3: accessed-variable=FSP1DiagInfoL3.FSP1DiagInfoL3
              REC_FSP1ResponseErrorL3_FSP1ResponseErrorL3: accessed-variable=FSP1ResponseErrorL3.FSP1ResponseErrorL3
              REC_FSP1SwitchStatusL3_FSP1SwitchStatusL3: accessed-variable=FSP1SwitchStatusL3.FSP1SwitchStatusL3
              REC_FSP2DiagInfoL3_FSP2DiagInfoL3: accessed-variable=FSP2DiagInfoL3.FSP2DiagInfoL3
              REC_FSP2ResponseErrorL3_FSP2ResponseErrorL3: accessed-variable=FSP2ResponseErrorL3.FSP2ResponseErrorL3
              REC_FSP2SwitchStatusL3_FSP2SwitchStatusL3: accessed-variable=FSP2SwitchStatusL3.FSP2SwitchStatusL3
              REC_LIN_TCP_ABS_ButtonStatus_LIN_TCP_ABS_ButtonStatus: accessed-variable=LIN_TCP_ABS_ButtonStatus.LIN_TCP_ABS_ButtonStatus
              REC_LIN_TCP_ATC_ButtonStatus_LIN_TCP_ATC_ButtonStatus: accessed-variable=LIN_TCP_ATC_ButtonStatus.LIN_TCP_ATC_ButtonStatus
              REC_LIN_TCP_ESC_ButtonStatus_LIN_TCP_ESC_ButtonStatus: accessed-variable=LIN_TCP_ESC_ButtonStatus.LIN_TCP_ESC_ButtonStatus
              REC_LIN_TCP_KnobPostionStatus_LIN_TCP_KnobPostionStatus: accessed-variable=LIN_TCP_KnobPostionStatus.LIN_TCP_KnobPostionStatus
              REC_LIN_TCP_TCS_ButtonStatus_LIN_TCP_TCS_ButtonStatus: accessed-variable=LIN_TCP_TCS_ButtonStatus.LIN_TCP_TCS_ButtonStatus
              REC_ResponseErrorTCP_ResponseErrorTCP: accessed-variable=ResponseErrorTCP.ResponseErrorTCP
              REC_SwitchDetectionNeeded1L3_SwitchDetectionNeeded1L3: accessed-variable=SwitchDetectionNeeded1L3.SwitchDetectionNeeded1L3
              REC_SwitchDetectionNeeded2L3_SwitchDetectionNeeded2L3: accessed-variable=SwitchDetectionNeeded2L3.SwitchDetectionNeeded2L3
              REC_SwitchDetectionResp1L3_SwitchDetectionResp1L3: accessed-variable=SwitchDetectionResp1L3.SwitchDetectionResp1L3
              REC_SwitchDetectionResp2L3_SwitchDetectionResp2L3: accessed-variable=SwitchDetectionResp2L3.SwitchDetectionResp2L3
              REC_DiagInfoCCFW_DiagInfoCCFW: accessed-variable=DiagInfoCCFW.DiagInfoCCFW
              REC_DiagInfoDLFW_DiagInfoDLFW: accessed-variable=DiagInfoDLFW.DiagInfoDLFW
              REC_DiagInfoELCP1_DiagInfoELCP1: accessed-variable=DiagInfoELCP1.DiagInfoELCP1
              REC_DiagInfoELCP2_DiagInfoELCP2: accessed-variable=DiagInfoELCP2.DiagInfoELCP2
              REC_DiagInfoILCP1_DiagInfoILCP1: accessed-variable=DiagInfoILCP1.DiagInfoILCP1
              REC_DiagInfoILCP2_DiagInfoILCP2: accessed-variable=DiagInfoILCP2.DiagInfoILCP2
              REC_DiagInfoLECM2_DiagInfoLECM2: accessed-variable=DiagInfoLECM2.DiagInfoLECM2
              REC_DiagInfoLECMBasic_DiagInfoLECMBasic: accessed-variable=DiagInfoLECMBasic.DiagInfoLECMBasic
              REC_DiagInfoRCECS_DiagInfoRCECS: accessed-variable=DiagInfoRCECS.DiagInfoRCECS
              REC_FSP1DiagInfoL1_FSP1DiagInfoL1: accessed-variable=FSP1DiagInfoL1.FSP1DiagInfoL1
              REC_FSP1DiagInfoL2_FSP1DiagInfoL2: accessed-variable=FSP1DiagInfoL2.FSP1DiagInfoL2
              REC_FSP1DiagInfoL4_FSP1DiagInfoL4: accessed-variable=FSP1DiagInfoL4.FSP1DiagInfoL4
              REC_FSP1DiagInfoL5_FSP1DiagInfoL5: accessed-variable=FSP1DiagInfoL5.FSP1DiagInfoL5
              REC_FSP1ResponseErrorL1_FSP1ResponseErrorL1: accessed-variable=FSP1ResponseErrorL1.FSP1ResponseErrorL1
              REC_FSP1ResponseErrorL2_FSP1ResponseErrorL2: accessed-variable=FSP1ResponseErrorL2.FSP1ResponseErrorL2
              REC_FSP1ResponseErrorL4_FSP1ResponseErrorL4: accessed-variable=FSP1ResponseErrorL4.FSP1ResponseErrorL4
              REC_FSP1ResponseErrorL5_FSP1ResponseErrorL5: accessed-variable=FSP1ResponseErrorL5.FSP1ResponseErrorL5
              REC_FSP1SwitchStatusL2_FSP1SwitchStatusL2: accessed-variable=FSP1SwitchStatusL2.FSP1SwitchStatusL2
              REC_FSP1SwitchStatusL4_FSP1SwitchStatusL4: accessed-variable=FSP1SwitchStatusL4.FSP1SwitchStatusL4
              REC_FSP1SwitchStatusL5_FSP1SwitchStatusL5: accessed-variable=FSP1SwitchStatusL5.FSP1SwitchStatusL5
              REC_FSP2DiagInfoL1_FSP2DiagInfoL1: accessed-variable=FSP2DiagInfoL1.FSP2DiagInfoL1
              REC_FSP2DiagInfoL2_FSP2DiagInfoL2: accessed-variable=FSP2DiagInfoL2.FSP2DiagInfoL2
              REC_FSP2ResponseErrorL1_FSP2ResponseErrorL1: accessed-variable=FSP2ResponseErrorL1.FSP2ResponseErrorL1
              REC_FSP2ResponseErrorL2_FSP2ResponseErrorL2: accessed-variable=FSP2ResponseErrorL2.FSP2ResponseErrorL2
              REC_FSP2SwitchStatusL1_FSP2SwitchStatusL1: accessed-variable=FSP2SwitchStatusL1.FSP2SwitchStatusL1
              REC_FSP2SwitchStatusL2_FSP2SwitchStatusL2: accessed-variable=FSP2SwitchStatusL2.FSP2SwitchStatusL2
              REC_FSP3DiagInfoL2_FSP3DiagInfoL2: accessed-variable=FSP3DiagInfoL2.FSP3DiagInfoL2
              REC_FSP3ResponseErrorL2_FSP3ResponseErrorL2: accessed-variable=FSP3ResponseErrorL2.FSP3ResponseErrorL2
              REC_FSP3SwitchStatusL2_FSP3SwitchStatusL2: accessed-variable=FSP3SwitchStatusL2.FSP3SwitchStatusL2
              REC_FSP4DiagInfoL2_FSP4DiagInfoL2: accessed-variable=FSP4DiagInfoL2.FSP4DiagInfoL2
              REC_FSP4ResponseErrorL2_FSP4ResponseErrorL2: accessed-variable=FSP4ResponseErrorL2.FSP4ResponseErrorL2
              REC_FSP4SwitchStatusL2_FSP4SwitchStatusL2: accessed-variable=FSP4SwitchStatusL2.FSP4SwitchStatusL2
              REC_LIN_AdjustButtonStatus_LIN_AdjustButtonStatus: accessed-variable=LIN_AdjustButtonStatus.LIN_AdjustButtonStatus
              REC_LIN_AlmClkSetCurAlm_rqst_sg_LIN_AlmClkSetCurAlm_rqst_sg: accessed-variable=LIN_AlmClkSetCurAlm_rqst_sg.LIN_AlmClkSetCurAlm_rqst_sg
              REC_LIN_BackButtonStatus_LIN_BackButtonStatus: accessed-variable=LIN_BackButtonStatus.LIN_BackButtonStatus
              REC_LIN_BackLightDimming_Status_LIN_BackLightDimming_Status: accessed-variable=LIN_BackLightDimming_Status.LIN_BackLightDimming_Status
              REC_LIN_BlackPanelMode_ButtonStat_LIN_BlackPanelMode_ButtonStat: accessed-variable=LIN_BlackPanelMode_ButtonStat.LIN_BlackPanelMode_ButtonStat
              REC_LIN_BunkBAudioOnOff_ButtonStat_LIN_BunkBAudioOnOff_ButtonStat: accessed-variable=LIN_BunkBAudioOnOff_ButtonStat.LIN_BunkBAudioOnOff_ButtonStat
              REC_LIN_BunkBIntLightActvnBtn_stat_LIN_BunkBIntLightActvnBtn_stat: accessed-variable=LIN_BunkBIntLightActvnBtn_stat.LIN_BunkBIntLightActvnBtn_stat
              REC_LIN_BunkBParkHeater_ButtonStat_LIN_BunkBParkHeater_ButtonStat: accessed-variable=LIN_BunkBParkHeater_ButtonStat.LIN_BunkBParkHeater_ButtonStat
              REC_LIN_BunkBTempDec_ButtonStat_LIN_BunkBTempDec_ButtonStat: accessed-variable=LIN_BunkBTempDec_ButtonStat.LIN_BunkBTempDec_ButtonStat
              REC_LIN_BunkBTempInc_ButtonStat_LIN_BunkBTempInc_ButtonStat: accessed-variable=LIN_BunkBTempInc_ButtonStat.LIN_BunkBTempInc_ButtonStat
              REC_LIN_BunkBVolumeDown_ButtonStat_LIN_BunkBVolumeDown_ButtonStat: accessed-variable=LIN_BunkBVolumeDown_ButtonStat.LIN_BunkBVolumeDown_ButtonStat
              REC_LIN_BunkBVolumeUp_ButtonStat_LIN_BunkBVolumeUp_ButtonStat: accessed-variable=LIN_BunkBVolumeUp_ButtonStat.LIN_BunkBVolumeUp_ButtonStat
              REC_LIN_BunkH2AudioOnOff_ButtonSta_LIN_BunkH2AudioOnOff_ButtonSta: accessed-variable=LIN_BunkH2AudioOnOff_ButtonSta.LIN_BunkH2AudioOnOff_ButtonSta
              REC_LIN_BunkH2Fade_ButtonStatus_LIN_BunkH2Fade_ButtonStatus: accessed-variable=LIN_BunkH2Fade_ButtonStatus.LIN_BunkH2Fade_ButtonStatus
              REC_LIN_BunkH2IntLightActvnBtn_sta_LIN_BunkH2IntLightActvnBtn_sta: accessed-variable=LIN_BunkH2IntLightActvnBtn_sta.LIN_BunkH2IntLightActvnBtn_sta
              REC_LIN_BunkH2IntLightDecBtn_stat_LIN_BunkH2IntLightDecBtn_stat: accessed-variable=LIN_BunkH2IntLightDecBtn_stat.LIN_BunkH2IntLightDecBtn_stat
              REC_LIN_BunkH2IntLightIncBtn_stat_LIN_BunkH2IntLightIncBtn_stat: accessed-variable=LIN_BunkH2IntLightIncBtn_stat.LIN_BunkH2IntLightIncBtn_stat
              REC_LIN_BunkH2LockButtonStatus_LIN_BunkH2LockButtonStatus: accessed-variable=LIN_BunkH2LockButtonStatus.LIN_BunkH2LockButtonStatus
              REC_LIN_BunkH2OnOFF_ButtonStatus_LIN_BunkH2OnOFF_ButtonStatus: accessed-variable=LIN_BunkH2OnOFF_ButtonStatus.LIN_BunkH2OnOFF_ButtonStatus
              REC_LIN_BunkH2PHTi_rqs_sg_LIN_BunkH2PHTi_rqs_sg: accessed-variable=LIN_BunkH2PHTi_rqs_sg.LIN_BunkH2PHTi_rqs_sg
              REC_LIN_BunkH2ParkHeater_ButtonSta_LIN_BunkH2ParkHeater_ButtonSta: accessed-variable=LIN_BunkH2ParkHeater_ButtonSta.LIN_BunkH2ParkHeater_ButtonSta
              REC_LIN_BunkH2Phone_ButtonStatus_LIN_BunkH2Phone_ButtonStatus: accessed-variable=LIN_BunkH2Phone_ButtonStatus.LIN_BunkH2Phone_ButtonStatus
              REC_LIN_BunkH2PowerWinCloseDSBtn_s_LIN_BunkH2PowerWinCloseDSBtn_s: accessed-variable=LIN_BunkH2PowerWinCloseDSBtn_s.LIN_BunkH2PowerWinCloseDSBtn_s
              REC_LIN_BunkH2PowerWinClosePSBtn_s_LIN_BunkH2PowerWinClosePSBtn_s: accessed-variable=LIN_BunkH2PowerWinClosePSBtn_s.LIN_BunkH2PowerWinClosePSBtn_s
              REC_LIN_BunkH2PowerWinOpenDSBtn_st_LIN_BunkH2PowerWinOpenDSBtn_st: accessed-variable=LIN_BunkH2PowerWinOpenDSBtn_st.LIN_BunkH2PowerWinOpenDSBtn_st
              REC_LIN_BunkH2PowerWinOpenPSBtn_st_LIN_BunkH2PowerWinOpenPSBtn_st: accessed-variable=LIN_BunkH2PowerWinOpenPSBtn_st.LIN_BunkH2PowerWinOpenPSBtn_st
              REC_LIN_BunkH2RoofhatchCloseBtn_St_LIN_BunkH2RoofhatchCloseBtn_St: accessed-variable=LIN_BunkH2RoofhatchCloseBtn_St.LIN_BunkH2RoofhatchCloseBtn_St
              REC_LIN_BunkH2RoofhatchOpenBtn_Sta_LIN_BunkH2RoofhatchOpenBtn_Sta: accessed-variable=LIN_BunkH2RoofhatchOpenBtn_Sta.LIN_BunkH2RoofhatchOpenBtn_Sta
              REC_LIN_BunkH2TempDec_ButtonStatus_LIN_BunkH2TempDec_ButtonStatus: accessed-variable=LIN_BunkH2TempDec_ButtonStatus.LIN_BunkH2TempDec_ButtonStatus
              REC_LIN_BunkH2TempInc_ButtonStatus_LIN_BunkH2TempInc_ButtonStatus: accessed-variable=LIN_BunkH2TempInc_ButtonStatus.LIN_BunkH2TempInc_ButtonStatus
              REC_LIN_BunkH2VolumeDown_ButtonSta_LIN_BunkH2VolumeDown_ButtonSta: accessed-variable=LIN_BunkH2VolumeDown_ButtonSta.LIN_BunkH2VolumeDown_ButtonSta
              REC_LIN_BunkH2VolumeUp_ButtonStatu_LIN_BunkH2VolumeUp_ButtonStatu: accessed-variable=LIN_BunkH2VolumeUp_ButtonStatu.LIN_BunkH2VolumeUp_ButtonStatu
              REC_LIN_DRL_ButtonStatus_LIN_DRL_ButtonStatus: accessed-variable=LIN_DRL_ButtonStatus.LIN_DRL_ButtonStatus
              REC_LIN_DifflockDeactivationBtn_st_LIN_DifflockDeactivationBtn_st: accessed-variable=LIN_DifflockDeactivationBtn_st.LIN_DifflockDeactivationBtn_st
              REC_LIN_DifflockMode_Wheelstatus_LIN_DifflockMode_Wheelstatus: accessed-variable=LIN_DifflockMode_Wheelstatus.LIN_DifflockMode_Wheelstatus
              REC_LIN_DoorAutoFuncBtn_stat_LIN_DoorAutoFuncBtn_stat: accessed-variable=LIN_DoorAutoFuncBtn_stat.LIN_DoorAutoFuncBtn_stat
              REC_LIN_EscButtonMuddySiteStatus_LIN_EscButtonMuddySiteStatus: accessed-variable=LIN_EscButtonMuddySiteStatus.LIN_EscButtonMuddySiteStatus
              REC_LIN_FCWPushButton_LIN_FCWPushButton: accessed-variable=LIN_FCWPushButton.LIN_FCWPushButton
              REC_LIN_FogLightFront_ButtonStat_1_LIN_FogLightFront_ButtonStat_1: accessed-variable=LIN_FogLightFront_ButtonStat_1.LIN_FogLightFront_ButtonStat_1
              REC_LIN_FogLightFront_ButtonStat_2_LIN_FogLightFront_ButtonStat_2: accessed-variable=LIN_FogLightFront_ButtonStat_2.LIN_FogLightFront_ButtonStat_2
              REC_LIN_FogLightRear_ButtonStat_1_LIN_FogLightRear_ButtonStat_1: accessed-variable=LIN_FogLightRear_ButtonStat_1.LIN_FogLightRear_ButtonStat_1
              REC_LIN_FogLightRear_ButtonStat_2_LIN_FogLightRear_ButtonStat_2: accessed-variable=LIN_FogLightRear_ButtonStat_2.LIN_FogLightRear_ButtonStat_2
              REC_LIN_HeadLampUpDown_SwitchStatu_LIN_HeadLampUpDown_SwitchStatu: accessed-variable=LIN_HeadLampUpDown_SwitchStatu.LIN_HeadLampUpDown_SwitchStatu
              REC_LIN_IntLghtCenterBtnFreeWhl_s_LIN_IntLghtCenterBtnFreeWhl_s: accessed-variable=LIN_IntLghtCenterBtnFreeWhl_s.LIN_IntLghtCenterBtnFreeWhl_s
              REC_LIN_IntLghtDimmingLvlDecBtn_s_LIN_IntLghtDimmingLvlDecBtn_s: accessed-variable=LIN_IntLghtDimmingLvlDecBtn_s.LIN_IntLghtDimmingLvlDecBtn_s
              REC_LIN_IntLghtDimmingLvlFreeWhl_s_LIN_IntLghtDimmingLvlFreeWhl_s: accessed-variable=LIN_IntLghtDimmingLvlFreeWhl_s.LIN_IntLghtDimmingLvlFreeWhl_s
              REC_LIN_IntLghtDimmingLvlIncBtn_s_LIN_IntLghtDimmingLvlIncBtn_s: accessed-variable=LIN_IntLghtDimmingLvlIncBtn_s.LIN_IntLghtDimmingLvlIncBtn_s
              REC_LIN_IntLghtMaxModeBtnPnl2_s_LIN_IntLghtMaxModeBtnPnl2_s: accessed-variable=LIN_IntLghtMaxModeBtnPnl2_s.LIN_IntLghtMaxModeBtnPnl2_s
              REC_LIN_IntLghtModeSelrFreeWheel_s_LIN_IntLghtModeSelrFreeWheel_s: accessed-variable=LIN_IntLghtModeSelrFreeWheel_s.LIN_IntLghtModeSelrFreeWheel_s
              REC_LIN_IntLghtNightModeBt2_s_LIN_IntLghtNightModeBt2_s: accessed-variable=LIN_IntLghtNightModeBt2_s.LIN_IntLghtNightModeBt2_s
              REC_LIN_IntLghtRestModeBtnPnl2_s_LIN_IntLghtRestModeBtnPnl2_s: accessed-variable=LIN_IntLghtRestModeBtnPnl2_s.LIN_IntLghtRestModeBtnPnl2_s
              REC_LIN_LKSPushButton_LIN_LKSPushButton: accessed-variable=LIN_LKSPushButton.LIN_LKSPushButton
              REC_LIN_LevelingThumbwheel_stat_LIN_LevelingThumbwheel_stat: accessed-variable=LIN_LevelingThumbwheel_stat.LIN_LevelingThumbwheel_stat
              REC_LIN_LightMode_Status_1_LIN_LightMode_Status_1: accessed-variable=LIN_LightMode_Status_1.LIN_LightMode_Status_1
              REC_LIN_LightMode_Status_2_LIN_LightMode_Status_2: accessed-variable=LIN_LightMode_Status_2.LIN_LightMode_Status_2
              REC_LIN_MemButtonStatus_LIN_MemButtonStatus: accessed-variable=LIN_MemButtonStatus.LIN_MemButtonStatus
              REC_LIN_Offroad_ButtonStatus_LIN_Offroad_ButtonStatus: accessed-variable=LIN_Offroad_ButtonStatus.LIN_Offroad_ButtonStatus
              REC_LIN_RearWorkProjector_BtnStat_LIN_RearWorkProjector_BtnStat: accessed-variable=LIN_RearWorkProjector_BtnStat.LIN_RearWorkProjector_BtnStat
              REC_LIN_SelectButtonStatus_LIN_SelectButtonStatus: accessed-variable=LIN_SelectButtonStatus.LIN_SelectButtonStatus
              REC_LIN_SpeedControlModeButtonStat_LIN_SpeedControlModeButtonStat: accessed-variable=LIN_SpeedControlModeButtonStat.LIN_SpeedControlModeButtonStat
              REC_LIN_SpeedControlModeWheelStat_LIN_SpeedControlModeWheelStat: accessed-variable=LIN_SpeedControlModeWheelStat.LIN_SpeedControlModeWheelStat
              REC_LIN_StopButtonStatus_LIN_StopButtonStatus: accessed-variable=LIN_StopButtonStatus.LIN_StopButtonStatus
              REC_LIN_WRDownButtonStatus_LIN_WRDownButtonStatus: accessed-variable=LIN_WRDownButtonStatus.LIN_WRDownButtonStatus
              REC_LIN_WRUpButtonStatus_LIN_WRUpButtonStatus: accessed-variable=LIN_WRUpButtonStatus.LIN_WRUpButtonStatus
              REC_ResponseErrorCCFW_ResponseErrorCCFW: accessed-variable=ResponseErrorCCFW.ResponseErrorCCFW
              REC_ResponseErrorDLFW_ResponseErrorDLFW: accessed-variable=ResponseErrorDLFW.ResponseErrorDLFW
              REC_ResponseErrorELCP1_ResponseErrorELCP1: accessed-variable=ResponseErrorELCP1.ResponseErrorELCP1
              REC_ResponseErrorELCP2_ResponseErrorELCP2: accessed-variable=ResponseErrorELCP2.ResponseErrorELCP2
              REC_ResponseErrorILCP1_ResponseErrorILCP1: accessed-variable=ResponseErrorILCP1.ResponseErrorILCP1
              REC_ResponseErrorILCP2_ResponseErrorILCP2: accessed-variable=ResponseErrorILCP2.ResponseErrorILCP2
              REC_ResponseErrorLECM2_ResponseErrorLECM2: accessed-variable=ResponseErrorLECM2.ResponseErrorLECM2
              REC_ResponseErrorLECMBasic_ResponseErrorLECMBasic: accessed-variable=ResponseErrorLECMBasic.ResponseErrorLECMBasic
              REC_ResponseErrorRCECS_ResponseErrorRCECS: accessed-variable=ResponseErrorRCECS.ResponseErrorRCECS
              REC_SwitchDetectionNeeded1L1_SwitchDetectionNeeded1L1: accessed-variable=SwitchDetectionNeeded1L1.SwitchDetectionNeeded1L1
              REC_SwitchDetectionNeeded1L2_SwitchDetectionNeeded1L2: accessed-variable=SwitchDetectionNeeded1L2.SwitchDetectionNeeded1L2
              REC_SwitchDetectionNeeded1L4_SwitchDetectionNeeded1L4: accessed-variable=SwitchDetectionNeeded1L4.SwitchDetectionNeeded1L4
              REC_SwitchDetectionNeeded1L5_SwitchDetectionNeeded1L5: accessed-variable=SwitchDetectionNeeded1L5.SwitchDetectionNeeded1L5
              REC_SwitchDetectionNeeded2L1_SwitchDetectionNeeded2L1: accessed-variable=SwitchDetectionNeeded2L1.SwitchDetectionNeeded2L1
              REC_SwitchDetectionNeeded{2..4}L2_SwitchDetectionNeeded{2..4}L2: accessed-variable=SwitchDetectionNeeded{2..4}L2.SwitchDetectionNeeded{2..4}L2
              REC_SwitchDetectionResp1L1_SwitchDetectionResp1L1: accessed-variable=SwitchDetectionResp1L1.SwitchDetectionResp1L1
              REC_SwitchDetectionResp1L2_SwitchDetectionResp1L2: accessed-variable=SwitchDetectionResp1L2.SwitchDetectionResp1L2
              REC_SwitchDetectionResp1L4_SwitchDetectionResp1L4: accessed-variable=SwitchDetectionResp1L4.SwitchDetectionResp1L4
              REC_SwitchDetectionResp1L5_SwitchDetectionResp1L5: accessed-variable=SwitchDetectionResp1L5.SwitchDetectionResp1L5
              REC_SwitchDetectionResp2L1_SwitchDetectionResp2L1: accessed-variable=SwitchDetectionResp2L1.SwitchDetectionResp2L1
              REC_SwitchDetectionResp{2..4}L2_SwitchDetectionResp{2..4}L2: accessed-variable=SwitchDetectionResp{2..4}L2.SwitchDetectionResp{2..4}L2
          data-send-points:
            52 x access:
              SEND_ABS_Indication_ABS_Indication: accessed-variable=ABS_Indication.ABS_Indication
              SEND_ATC_Indication_ATC_Indication: accessed-variable=ATC_Indication.ATC_Indication
              SEND_BswM_SRI_BswM_MSI_BswMRteMDG_LIN3Schedule_BswM_MDGP_BswMRteMDG_LIN3Schedule_requestedMode: accessed-variable=BswM_SRI_BswM_MSI_BswMRteMDG_LIN3Schedule_BswM_MDGP_BswMRteMDG_LIN3Schedule.requestedMode
              SEND_ESC_Indication_ESC_Indication: accessed-variable=ESC_Indication.ESC_Indication
              SEND_FSP1IndicationCmdL3_FSP1IndicationCmdL3: accessed-variable=FSP1IndicationCmdL3.FSP1IndicationCmdL3
              SEND_FSP2IndicationCmdL3_FSP2IndicationCmdL3: accessed-variable=FSP2IndicationCmdL3.FSP2IndicationCmdL3
              SEND_TCS_Indication_TCS_Indication: accessed-variable=TCS_Indication.TCS_Indication
              SEND_BswM_SRI_BswM_MSI_BswMRteMDG_LIN1Schedule_BswM_MDGP_BswMRteMDG_LIN1Schedule_requestedMode: accessed-variable=BswM_SRI_BswM_MSI_BswMRteMDG_LIN1Schedule_BswM_MDGP_BswMRteMDG_LIN1Schedule.requestedMode
              SEND_BswM_SRI_BswM_MSI_BswMRteMDG_LIN2Schedule_BswM_MDGP_BswMRteMDG_LIN2Schedule_requestedMode: accessed-variable=BswM_SRI_BswM_MSI_BswMRteMDG_LIN2Schedule_BswM_MDGP_BswMRteMDG_LIN2Schedule.requestedMode
              SEND_BswM_SRI_BswM_MSI_BswMRteMDG_LIN4Schedule_BswM_MDGP_BswMRteMDG_LIN4Schedule_requestedMode: accessed-variable=BswM_SRI_BswM_MSI_BswMRteMDG_LIN4Schedule_BswM_MDGP_BswMRteMDG_LIN4Schedule.requestedMode
              SEND_BswM_SRI_BswM_MSI_BswMRteMDG_LIN5Schedule_BswM_MDGP_BswMRteMDG_LIN5Schedule_requestedMode: accessed-variable=BswM_SRI_BswM_MSI_BswMRteMDG_LIN5Schedule_BswM_MDGP_BswMRteMDG_LIN5Schedule.requestedMode
              SEND_DoorLock_stat_DoorLock_stat: accessed-variable=DoorLock_stat.DoorLock_stat
              SEND_FSP1IndicationCmdL2_FSP1IndicationCmdL2: accessed-variable=FSP1IndicationCmdL2.FSP1IndicationCmdL2
              SEND_FSP1IndicationCmdL4_FSP1IndicationCmdL4: accessed-variable=FSP1IndicationCmdL4.FSP1IndicationCmdL4
              SEND_FSP1IndicationCmdL5_FSP1IndicationCmdL5: accessed-variable=FSP1IndicationCmdL5.FSP1IndicationCmdL5
              SEND_FSP2IndicationCmdL1_FSP2IndicationCmdL1: accessed-variable=FSP2IndicationCmdL1.FSP2IndicationCmdL1
              SEND_FSP{2..4}IndicationCmdL2_FSP{2..4}IndicationCmdL2: accessed-variable=FSP{2..4}IndicationCmdL2.FSP{2..4}IndicationCmdL2
              SEND_LIN_ACCOrCCIndication_LIN_ACCOrCCIndication: accessed-variable=LIN_ACCOrCCIndication.LIN_ACCOrCCIndication
              SEND_LIN_ASLIndication_LIN_ASLIndication: accessed-variable=LIN_ASLIndication.LIN_ASLIndication
              SEND_LIN_Adjust_DeviceIndication_LIN_Adjust_DeviceIndication: accessed-variable=LIN_Adjust_DeviceIndication.LIN_Adjust_DeviceIndication
              SEND_LIN_AlmClkCurAlarm_stat_sg_LIN_AlmClkCurAlarm_stat_sg: accessed-variable=LIN_AlmClkCurAlarm_stat_sg.LIN_AlmClkCurAlarm_stat_sg
              SEND_LIN_AudioSystemStatus_LIN_AudioSystemStatus: accessed-variable=LIN_AudioSystemStatus.LIN_AudioSystemStatus
              SEND_LIN_AudioVolumeIndicationCmd_LIN_AudioVolumeIndicationCmd: accessed-variable=LIN_AudioVolumeIndicationCmd.LIN_AudioVolumeIndicationCmd
              SEND_LIN_BTStatus_LIN_BTStatus: accessed-variable=LIN_BTStatus.LIN_BTStatus
              SEND_LIN_DaytimeRunningLight_Indica_LIN_DaytimeRunningLight_Indica: accessed-variable=LIN_DaytimeRunningLight_Indica.LIN_DaytimeRunningLight_Indica
              SEND_LIN_DifflockOnOff_Indication_LIN_DifflockOnOff_Indication: accessed-variable=LIN_DifflockOnOff_Indication.LIN_DifflockOnOff_Indication
              SEND_LIN_DoorAutoFuncInd_cmd_LIN_DoorAutoFuncInd_cmd: accessed-variable=LIN_DoorAutoFuncInd_cmd.LIN_DoorAutoFuncInd_cmd
              SEND_LIN_Down_DeviceIndication_LIN_Down_DeviceIndication: accessed-variable=LIN_Down_DeviceIndication.LIN_Down_DeviceIndication
              SEND_LIN_DrivingLightPlus_Indicatio_LIN_DrivingLightPlus_Indicatio: accessed-variable=LIN_DrivingLightPlus_Indicatio.LIN_DrivingLightPlus_Indicatio
              SEND_LIN_DrivingLight_Indication_LIN_DrivingLight_Indication: accessed-variable=LIN_DrivingLight_Indication.LIN_DrivingLight_Indication
              SEND_LIN_EscButtonMuddySiteDeviceIn_LIN_EscButtonMuddySiteDeviceIn: accessed-variable=LIN_EscButtonMuddySiteDeviceIn.LIN_EscButtonMuddySiteDeviceIn
              SEND_LIN_FCW_DeviceIndication_LIN_FCW_DeviceIndication: accessed-variable=LIN_FCW_DeviceIndication.LIN_FCW_DeviceIndication
              SEND_LIN_FrontFog_Indication_LIN_FrontFog_Indication: accessed-variable=LIN_FrontFog_Indication.LIN_FrontFog_Indication
              SEND_LIN_IntLghtLvlIndScaled_cmd_LIN_IntLghtLvlIndScaled_cmd: accessed-variable=LIN_IntLghtLvlIndScaled_cmd.LIN_IntLghtLvlIndScaled_cmd
              SEND_LIN_IntLghtModeInd_cmd_sg_LIN_IntLghtModeInd_cmd_sg: accessed-variable=LIN_IntLghtModeInd_cmd_sg.LIN_IntLghtModeInd_cmd_sg
              SEND_LIN_IntLghtOffModeInd_cmd_LIN_IntLghtOffModeInd_cmd: accessed-variable=LIN_IntLghtOffModeInd_cmd.LIN_IntLghtOffModeInd_cmd
              SEND_LIN_IntLightMaxModeInd_cmd_LIN_IntLightMaxModeInd_cmd: accessed-variable=LIN_IntLightMaxModeInd_cmd.LIN_IntLightMaxModeInd_cmd
              SEND_LIN_IntLightNightModeInd_cmd_LIN_IntLightNightModeInd_cmd: accessed-variable=LIN_IntLightNightModeInd_cmd.LIN_IntLightNightModeInd_cmd
              SEND_LIN_IntLightRestingModeInd_cmd_LIN_IntLightRestingModeInd_cmd: accessed-variable=LIN_IntLightRestingModeInd_cmd.LIN_IntLightRestingModeInd_cmd
              SEND_LIN_LKS_DeviceIndication_LIN_LKS_DeviceIndication: accessed-variable=LIN_LKS_DeviceIndication.LIN_LKS_DeviceIndication
              SEND_LIN_M{1..3}_DeviceIndication_LIN_M{1..3}_DeviceIndication: accessed-variable=LIN_M{1..3}_DeviceIndication.LIN_M{1..3}_DeviceIndication
              SEND_LIN_Offroad_Indication_LIN_Offroad_Indication: accessed-variable=LIN_Offroad_Indication.LIN_Offroad_Indication
              SEND_LIN_ParkingLight_Indication_LIN_ParkingLight_Indication: accessed-variable=LIN_ParkingLight_Indication.LIN_ParkingLight_Indication
              SEND_LIN_PhoneButtonIndication_cmd_LIN_PhoneButtonIndication_cmd: accessed-variable=LIN_PhoneButtonIndication_cmd.LIN_PhoneButtonIndication_cmd
              SEND_LIN_RearFog_Indication_LIN_RearFog_Indication: accessed-variable=LIN_RearFog_Indication.LIN_RearFog_Indication
              SEND_LIN_RearWorkProjector_Indicati_LIN_RearWorkProjector_Indicati: accessed-variable=LIN_RearWorkProjector_Indicati.LIN_RearWorkProjector_Indicati
              SEND_LIN_ShortPulseMaxLength_LIN_ShortPulseMaxLength: accessed-variable=LIN_ShortPulseMaxLength.LIN_ShortPulseMaxLength
              SEND_LIN_Up_DeviceIndication_LIN_Up_DeviceIndication: accessed-variable=LIN_Up_DeviceIndication.LIN_Up_DeviceIndication
        Re_LIN0_FSP1_L1_FSP1DiagInfoL1_RxTimeout
        Re_LIN0_FSP2_L1_FSP2DiagInfoL1_RxTimeout
        Re_LIN0_ILCP1_DiagInfoILCP1_RxTimeout
        Re_LIN0_FSP1_L1_FSP1ResponseErrorL1_RxTimeout
        Re_LIN0_FSP1_L1_SwitchDetectionNeeded1L1_RxTimeout
        Re_LIN0_FSP2_L1_FSP2ResponseErrorL1_RxTimeout
        Re_LIN0_FSP2_L1_FSP2SwitchStatusL1_RxTimeout
        Re_LIN0_FSP2_L1_SwitchDetectionNeeded2L1_RxTimeout
        Re_LIN0_ILCP1_LIN_DoorAutoFuncBtn_stat_RxTimeout
        Re_LIN0_ILCP1_LIN_IntLghtDimmingLvlDecBtn_s_RxTimeout
        Re_LIN0_ILCP1_LIN_IntLghtDimmingLvlIncBtn_s_RxTimeout
        Re_LIN0_ILCP1_LIN_IntLghtModeSelrFreeWheel_s_RxTimeout
        Re_LIN0_ILCP1_ResponseErrorILCP1_RxTimeout
        Re_LIN0_FSP1_L1_FSP1DiagInfoL1_RXCbk
        Re_LIN0_FSP1_L1_FSP1ResponseErrorL1_RXCbk
        Re_LIN0_FSP1_L1_SwitchDetectionNeeded1L1_RXCbk
        Re_LIN0_FSP2_L1_FSP2DiagInfoL1_RXCbk
        Re_LIN0_FSP2_L1_FSP2ResponseErrorL1_RXCbk
        Re_LIN0_FSP2_L1_FSP2SwitchStatusL1_RXCbk
        Re_LIN0_FSP2_L1_SwitchDetectionNeeded2L1_RXCbk
        Re_LIN0_ILCP1_DiagInfoILCP1_RXCbk
        Re_LIN0_ILCP1_LIN_DoorAutoFuncBtn_stat_RXCbk
        Re_LIN0_ILCP1_LIN_IntLghtDimmingLvlDecBtn_s_RXCbk
        Re_LIN0_ILCP1_LIN_IntLghtDimmingLvlIncBtn_s_RXCbk
        Re_LIN0_ILCP1_LIN_IntLghtModeSelrFreeWheel_s_RXCbk
        Re_LIN0_ILCP1_ResponseErrorILCP1_RXCbk
  swc implementation TestLin_Implementation: behavior=TestLin_InternalBehavior
